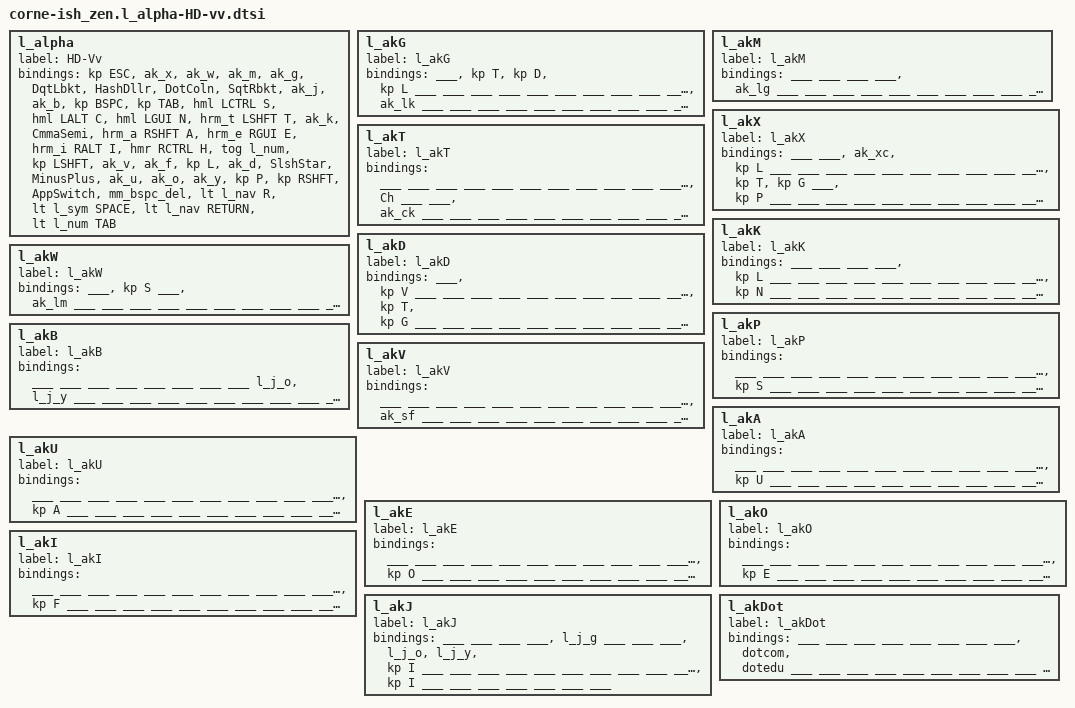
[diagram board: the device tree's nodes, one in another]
/*  Base (alpha) Layer  Hands Down Vibranium-vv
    Building for a 36 keys on a 42 key board
     ╭─────────────────────╮ ╭──────────────────────╮
ESC  │  X   W   M   G  "[  │ │  #$  .:  ']   J   B  │ BSP
TAB  │  S   C   N   T   K  | |  ,;   A   E   I   H  │ Tg(Num)
LSFT │  V   P   L   D   /* │ │  -+   U   O   Y   F  │ RSFT
     ╰──────╮  App BSP  R  │ │  SPC RET TAB  ╭──────╯
            ╰──────────────╯ ╰───────────────╯
*/


                l_alpha {
                        label = "HD-Vv";
                        bindings = <

&kp ESC  &ak_x        &ak_w      &ak_m     &ak_g     &DqtLbkt            &HashDllr   &DotColn   &SqtRbkt       &ak_j      &ak_b &kp BSPC
&kp TAB &hml LCTRL S &hml LALT C   &hml LGUI N  &hrm_t LSHFT T &ak_k    &CmmaSemi   &hrm_a RSHFT A &hrm_e RGUI E  &hrm_i RALT I  &hmr RCTRL H &tog l_num
&kp LSHFT &ak_v  &ak_f &kp L      &ak_d     &SlshStar           &MinusPlus  &ak_u      &ak_o          &ak_y      &kp P &kp RSHFT


                        &AppSwitch &mm_bspc_del &lt l_nav R      &lt l_sym SPACE &lt l_nav RETURN  &lt l_num TAB
                        >;
                };

                l_akG {
                        label = "l_akG";
                        bindings = <

___     &kp T   &kp D   &kp L   ___     ___     ___     ___     ___     ___     ___     ___
___     ___     ___     ___     ___    &ak_lk   ___     ___     ___     ___     ___     ___
___     ___     ___     ___     ___     ___     ___     ___     ___     ___     ___     ___
                        ___     ___     ___     ___     ___     ___
                        >;
                };
                l_akM {
                        label = "l_akM";
                        bindings = <

___     ___     ___     ___    &ak_lg   ___     ___     ___     ___     ___     ___     ___
___     ___     ___     ___     ___     ___     ___     ___     ___     ___     ___     ___
___     ___     ___     ___     ___     ___     ___     ___     ___     ___     ___     ___
                        ___     ___     ___     ___     ___     ___
                        >;
                };
                l_akX {
                        label = "l_akX";
                        bindings = <

___     ___     &ak_xc  &kp L  ___      ___     ___     ___     ___     ___     ___     ___
___     ___     ___     ___    ___      ___     ___     ___     ___     ___     ___     ___
___     &kp T   &kp G   ___    &kp P    ___     ___     ___     ___     ___     ___     ___
                        ___     ___     ___     ___     ___     ___
                        >;
                };
                l_akT {
                        label = "l_akT";
                        bindings = <

___     ___     ___     ___     ___     ___     ___     ___     ___     ___     ___     ___
___     ___     &Ch     ___     ___     &ak_ck  ___     ___     ___     ___     ___     ___
___     ___     ___     ___     ___     ___     ___     ___     ___     ___     ___     ___
                        ___     ___     ___     ___     ___     ___
                        >;
                };
                l_akK {
                        label = "l_akK";
                        bindings = <

___     ___     ___     ___     &kp L   ___     ___     ___     ___     ___     ___     ___
___     ___     ___     ___     &kp N   ___     ___     ___     ___     ___     ___     ___
___     ___     ___     ___     ___     ___     ___     ___     ___     ___     ___     ___
                        ___     ___     ___     ___     ___     ___
                        >;
                };
                l_akD {
                        label = "l_akD";
                        bindings = <

___     &kp V   ___     ___     ___     ___    ___     ___     ___     ___     ___     ___
___     ___     ___     ___     ___     ___    ___     ___     ___     ___     ___     ___
___     &kp T   &kp G   ___     ___     ___    ___     ___     ___     ___     ___     ___
                        ___     ___     ___    ___     ___     ___
                        >;
                };
                l_akW {
                        label = "l_akW";
                        bindings = <

___     &kp S   ___     &ak_lm  ___     ___     ___     ___     ___     ___     ___     ___
___     ___     ___     ___     ___     ___     ___     ___     ___     ___     ___     ___
___     ___     ___     ___     ___     ___     ___     ___     ___     ___     ___     ___
                        ___     ___     ___     ___     ___     ___
                        >;
                };
                l_akP {
                        label = "l_akP";
                        bindings = <

___     ___     ___     ___     ___     ___     ___     ___     ___     ___     ___     ___
___     ___     ___     ___     ___     ___     ___     ___     ___     ___     ___     ___
___     &kp S   ___     ___     ___     ___     ___     ___     ___     ___     ___     ___
                        ___     ___     ___     ___     ___     ___
                        >;
                };
                l_akB {
                        label = "l_akB";
                        bindings = <

___     ___     ___     ___     ___     ___     ___     ___     l_j_o  &l_j_y   ___     ___
___     ___     ___     ___     ___     ___     ___     ___     ___     ___     ___     ___
___     ___     ___     ___     ___     ___     ___     ___     ___     ___     ___     ___
                        ___     ___     ___     ___     ___     ___
                        >;
                };
                l_akV {
                        label = "l_akV";
                        bindings = <

___     ___     ___     ___     ___     ___     ___     ___     ___     ___     ___     ___
___     ___     ___     ___     ___     ___     ___     ___     ___     ___     ___     ___
___     ___     &ak_sf  ___     ___     ___     ___     ___     ___     ___     ___     ___
                        ___     ___     ___     ___     ___     ___
                        >;
                };


                l_akA {
                        label = "l_akA";
                        bindings = <

___     ___     ___     ___     ___     ___     ___     ___     ___     ___     ___     ___
___     ___     ___     ___     ___     ___     ___     ___     ___     ___     &kp U   ___
___     ___     ___     ___     ___     ___     ___     ___     ___     ___     ___     ___
                        ___     ___     ___     ___     ___     ___
                        >;
                };

                l_akU {
                        label = "l_akU";
                        bindings = <

___     ___     ___     ___     ___     ___     ___     ___     ___     ___     ___     ___
___     ___     ___     ___     ___     ___     ___     ___     ___     ___     &kp A   ___
___     ___     ___     ___     ___     ___     ___     ___     ___     ___     ___     ___
                        ___     ___     ___     ___     ___     ___
                        >;
                };

                l_akE {
                        label = "l_akE";
                        bindings = <

___     ___     ___     ___     ___     ___     ___     ___     ___     ___     ___     ___
___     ___     ___     ___     ___     ___     ___     ___     ___     ___     &kp O   ___
___     ___     ___     ___     ___     ___     ___     ___     ___     ___     ___     ___
                        ___     ___     ___     ___     ___     ___
                        >;
                };
                l_akO {
                        label = "l_akO";
                        bindings = <

___     ___     ___     ___     ___     ___     ___     ___     ___     ___     ___     ___
___     ___     ___     ___     ___     ___     ___     ___     ___     ___     &kp E   ___
___     ___     ___     ___     ___     ___     ___     ___     ___     ___     ___     ___
                        ___     ___     ___     ___     ___     ___
                        >;
                };
                l_akI {
                        label = "l_akI";
                        bindings = <

___     ___     ___     ___     ___     ___     ___     ___     ___     ___     ___     ___
___     ___     ___     ___     ___     ___     ___     ___     ___     ___     &kp F   ___
___     ___     ___     ___     ___     ___     ___     ___     ___     ___     ___     ___
                        ___     ___     ___     ___     ___     ___
                        >;
                };
                l_akJ {
                        label = "l_akJ";
                        bindings = <

___     ___     ___     ___     &l_j_g  ___    ___     ___     &l_j_o  &l_j_y   &kp I   ___
___     ___     ___     ___     ___     ___    ___     ___     ___     ___      ___     ___
___     ___     ___     ___     ___     ___    ___     ___     ___     ___      &kp I   ___
                ___     ___     ___    ___     ___     ___
                        >;
                };

                l_akDot {
                        label = "l_akDot";
                        bindings = <

___     ___     ___     ___     ___     ___     ___     ___     &dotcom &dotedu ___     ___
___     ___     ___     ___     ___     ___     ___     ___     ___     ___     ___     ___
___     ___     ___     ___     ___     ___     ___     ___     ___     ___     ___     ___
                        ___     ___     ___     ___     ___     ___
                        >;
                };
